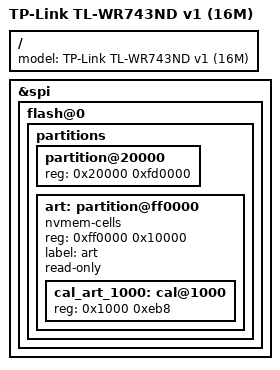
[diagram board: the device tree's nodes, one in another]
// SPDX-License-Identifier: GPL-2.0-or-later OR MIT
/dts-v1/;

#include "ar7240_tplink_tl-wr743nd-v1.dts"

/ {
	model = "TP-Link TL-WR743ND v1 (16M)";
};

&spi {
	flash@0 {
		partitions {
			partition@20000 {
				reg = <0x20000 0xfd0000>;
			};

			/delete-node/ partition@3f0000;
			art: partition@ff0000 {
				reg = <0xff0000 0x10000>;
				label = "art";
				read-only;
			};
		};
	};
};

&art {
	compatible = "nvmem-cells";
	#address-cells = <1>;
	#size-cells = <1>;

	cal_art_1000: cal@1000 {
		reg = <0x1000 0xeb8>;
	};
};
